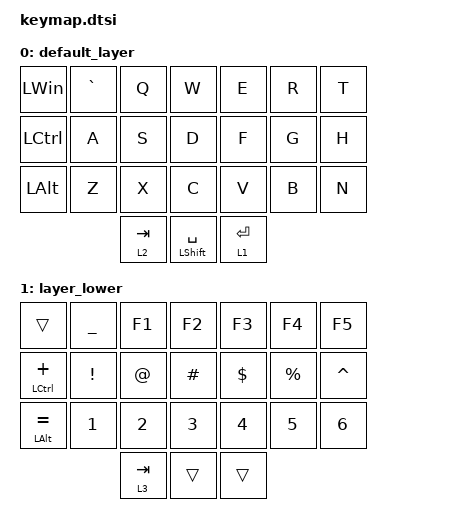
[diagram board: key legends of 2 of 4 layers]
/* SPDX-License-Identifier: MIT */
#include <behaviors.dtsi>
#include <dt-bindings/zmk/bt.h>
#include <dt-bindings/zmk/keys.h>
#include <dt-bindings/zmk/rgb.h>

/ {
    keymap {
        compatible = "zmk,keymap";

        default_layer {
            bindings = <
            &kp LWIN  &kp GRAVE  &kp Q  &kp W  &kp E      &kp R            &kp T
            &kp LCTRL &kp A     &kp S  &kp D  &kp F      &kp G            &kp H
            &kp LALT  &kp Z     &kp X  &kp C  &kp V      &kp B            &kp N
            &lt 2 TAB  &mt LSHFT SPACE  &lt 1 RET
            >;
        };

        layer_lower {
            bindings = <
            &trans  &kp UNDER       &kp F1    &kp F2  &kp F3     &kp F4    &kp F5
            &mt LCTRL PLUS  &kp EXCL  &kp AT  &kp HASH   &kp DLLR  &kp PRCNT  &kp CARET
            &mt LALT EQUAL  &kp N1    &kp N2  &kp N3     &kp N4    &kp N5     &kp N6
            &lt 3 TAB  &trans    &trans
            >;
        };

        layer_raise {
            bindings = <
            &trans  &kp KP_NUM       &kp KP_SLASH     &kp KP_N7  &kp KP_N8  &kp KP_N9  &kp KP_MINUS
            &mt LCTRL EQUAL  &kp KP_MULTIPLY  &kp KP_N4  &kp KP_N5  &kp KP_N6  &kp KP_PLUS
            &trans           &kp KP_N0        &kp KP_N1  &kp KP_N2  &kp KP_N3  &kp KP_DOT
            &trans     &trans
            >;
        };

        layer_adjust {
            bindings = <
            &sys_reset  &bootloader      &none            &none            &none            &none
            &bt BT_CLR       &bt BT_SEL 0     &bt BT_SEL 1     &bt BT_SEL 2     &bt BT_SEL 3     &bt BT_SEL 4
            &rgb_ug RGB_OFF  &rgb_ug RGB_EFF  &rgb_ug RGB_HUI  &rgb_ug RGB_SAI  &rgb_ug RGB_BRI  &rgb_ug RGB_BRD
            &trans           &none            &trans
            >;
        };
    };
};
